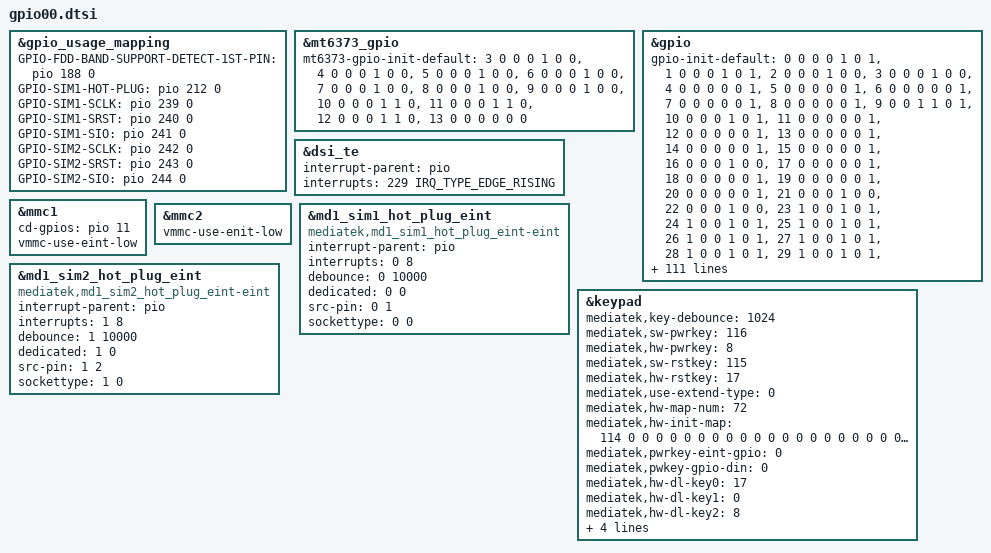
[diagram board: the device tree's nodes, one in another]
// SPDX-License-Identifier: (GPL-2.0 OR MIT)
/*
 * Copyright (C) 2022 MediaTek Inc.
 */
/*
 * Generated by MTK SP DrvGen Version: 3.5.160809 for MT6989.
 * 2024-03-19 13:16:16
 * Do Not Modify The File.
 * Copyright Mediatek Inc. (c) 2016.
 */

/*************************
 * ADC DTSI File
 ************************/



/*************************
 * CLK_BUF DTSI File
 ************************/



/*************************
 * I2C DTSI File
 ************************/



/*************************
 * GPIO DTSI File
 ************************/

&gpio_usage_mapping {
	GPIO-FDD-BAND-SUPPORT-DETECT-1ST-PIN = <&pio 188 0>;
	GPIO-SIM1-HOT-PLUG = <&pio 212 0>;
	GPIO-SIM1-SCLK = <&pio 239 0>;
	GPIO-SIM1-SRST = <&pio 240 0>;
	GPIO-SIM1-SIO = <&pio 241 0>;
	GPIO-SIM2-SCLK = <&pio 242 0>;
	GPIO-SIM2-SRST = <&pio 243 0>;
	GPIO-SIM2-SIO = <&pio 244 0>;
};

&mt6373_gpio{
	/* gpio1 and gpio2 has been reserved */
	mt6373-gpio-init-default = <3 0 0 0 1 0 0>,
	<4 0 0 0 1 0 0>,
	<5 0 0 0 1 0 0>,
	<6 0 0 0 1 0 0>,
	<7 0 0 0 1 0 0>,
	<8 0 0 0 1 0 0>,
	<9 0 0 0 1 0 0>,
	<10 0 0 0 1 1 0>,
	<11 0 0 0 1 1 0>,
	<12 0 0 0 1 1 0>,
	<13 0 0 0 0 0 0>;
};


&gpio{
	gpio-init-default = <0 0 0 0 1 0 1>,
		<1 0 0 0 1 0 1>,
		<2 0 0 0 1 0 0>,	/* NC */
		<3 0 0 0 1 0 0>,	/* TCON_RDY */
		<4 0 0 0 0 0 1>,
		<5 0 0 0 0 0 1>,
		<6 0 0 0 0 0 1>,
		<7 0 0 0 0 0 1>,
		<8 0 0 0 0 0 1>,
		<9 0 0 1 1 0 1>,
		<10 0 0 0 1 0 1>,
		<11 0 0 0 0 0 1>,
		<12 0 0 0 0 0 1>,
		<13 0 0 0 0 0 1>,
		<14 0 0 0 0 0 1>,
		<15 0 0 0 0 0 1>,
		<16 0 0 0 1 0 0>,	/* TCON_INT */
		<17 0 0 0 0 0 1>,
		<18 0 0 0 0 0 1>,
		<19 0 0 0 0 0 1>,
		<20 0 0 0 0 0 1>,
		<21 0 0 0 1 0 0>,	/* NC */
		<22 0 0 0 1 0 0>,	/* NC */
		<23 1 0 0 1 0 1>,
		<24 1 0 0 1 0 1>,
		<25 1 0 0 1 0 1>,
		<26 1 0 0 1 0 1>,
		<27 1 0 0 1 0 1>,
		<28 1 0 0 1 0 1>,
		<29 1 0 0 1 0 1>,
		<30 0 0 0 1 0 0>,
		<31 0 0 0 1 0 0>,
		<32 0 0 0 0 0 0>,
		<33 0 0 0 0 0 0>,
		<34 1 0 0 0 0 0>,
		<35 1 0 0 1 0 0>,
		<36 1 0 0 1 0 1>,
		<37 1 0 0 1 0 1>,
		<38 1 0 0 1 0 1>,
		<39 1 0 0 1 0 1>,
		<40 0 0 0 1 0 1>,
		<41 0 0 0 1 0 1>,
		<42 0 0 0 1 0 1>,
		<43 0 0 0 1 0 1>,
		<44 0 0 0 1 0 1>,
		<45 0 0 0 1 0 1>,
		<46 0 0 0 1 0 1>,
		<47 0 0 0 1 0 1>,
		<48 0 0 0 1 0 1>,
		<49 0 0 0 1 0 1>,
		<50 0 0 0 1 0 1>,
		<51 1 0 0 0 0 1>,
		<52 1 0 0 0 0 1>,
		<53 0 0 0 1 0 1>,
		<54 0 0 0 1 0 1>,
		<55 2 0 0 0 0 0>,
		<56 2 0 0 1 0 0>,
		<57 0 0 0 1 0 1>,
		<58 1 0 0 0 0 1>,
		<59 0 0 0 1 0 1>,
		<60 0 0 0 1 0 1>,
		<61 0 0 0 0 0 1>,
		<62 2 0 0 0 0 1>,
		<63 2 0 0 0 0 1>,
		<64 2 0 0 0 0 1>,
		<65 2 0 0 0 0 1>,
		<66 0 1 0 1 0 1>,
		<67 0 1 0 1 0 1>,
		<68 0 1 0 1 0 1>,
		<69 0 1 0 1 0 1>,
		<70 0 0 0 0 0 1>,
		<71 0 0 0 0 0 1>,
		<72 1 0 0 0 0 1>,
		<73 1 0 0 0 0 1>,
		<74 0 0 0 1 0 1>,
		<75 0 0 0 1 0 1>,
		<76 0 0 0 1 0 1>,
		<77 0 0 0 1 0 1>,
		<78 0 0 0 1 0 1>,	/* snvm i2c scl*/
		<79 0 0 0 1 0 1>,	/* snvm i2c sda */
		<80 0 0 0 1 0 0>,	/* NC */
		<81 0 0 0 1 0 1>,
		<82 0 0 0 1 0 1>,
		<83 0 0 0 1 0 1>,
		<84 0 1 0 0 0 1>,	/* aux switch sel */
		<85 0 0 0 0 0 1>,
		<86 0 1 0 0 2 0>,	/* OCTA_DCDC_EN */
		<87 0 1 1 0 0 1>,	/* aux switch en */
		<88 0 0 0 1 0 1>,
		<89 0 0 0 1 0 1>,
		<90 0 0 0 0 0 1>,
		<91 0 0 0 0 0 1>,
		<92 0 0 0 1 0 1>,
		<93 0 0 0 1 0 1>,
		<94 0 0 0 0 0 1>,
		<95 0 0 0 0 0 1>,
		<96 0 1 0 1 0 1>,
		<97 0 1 0 1 0 1>,
		<98 1 0 0 1 1 1>,
		<99 1 0 0 1 1 1>,
		<100 1 0 0 1 1 1>,
		<101 1 0 0 1 1 1>,
		<102 1 0 0 1 1 1>,
		<103 1 0 0 1 1 1>,
		<104 2 0 0 0 0 1>,
		<105 2 0 0 0 0 1>,
		<106 0 1 0 1 0 1>,	/* VTCAM_MCLK */
		<107 0 1 0 1 0 1>,
		<108 0 1 0 1 0 1>,
		<109 0 1 0 1 0 1>,
		<110 0 1 0 1 0 1>,
		<111 0 1 1 1 0 1>,
		<112 0 1 0 1 0 1>,
		<113 0 1 0 1 0 1>,
		<114 0 0 0 0 0 1>,
		<115 0 0 0 0 0 1>,
		<116 0 1 0 1 0 1>,	/* MAINCAM_MCLK */
		<117 0 1 0 1 0 1>,	/* UWCAM_MCLK */
		<118 0 0 0 1 0 1>,
		<119 0 0 0 1 0 1>,
		<120 1 0 0 1 1 1>,
		<121 1 0 0 1 1 1>,
		<122 0 0 0 1 0 0>,	/* NC */
		<123 0 0 0 1 0 0>,	/* NC */
		<124 0 1 0 1 0 1>,
		<125 0 1 0 1 0 1>,
		<126 0 0 0 1 0 0>,	/* NC */
		<127 0 0 0 1 0 0>,	/* NC */
		<128 1 0 0 1 1 1>,
		<129 1 0 0 1 1 1>,
		<130 1 0 0 1 1 1>,
		<131 1 0 0 1 1 1>,
		<132 1 0 0 1 0 1>,
		<133 1 0 0 1 0 1>,
		<134 1 0 0 1 0 1>,
		<135 0 0 0 1 0 1>,
		<136 0 0 0 1 0 1>,
		<137 0 0 0 1 0 1>,
		<138 0 0 0 1 0 1>,
		<139 0 0 0 0 0 1>,
		<140 0 0 0 0 0 1>,
		<141 1 0 0 0 0 1>,
		<142 1 0 0 1 1 1>,
		<143 1 0 0 1 0 1>,
		<144 1 0 0 1 0 1>,
		<145 1 0 0 1 0 1>,
		<146 1 0 0 1 0 1>,
		<147 1 0 0 1 0 1>,
		<148 1 0 0 0 0 1>,
		<149 1 0 0 1 1 1>,
		<150 0 1 0 1 0 1>,
		<151 0 1 0 1 0 1>,
		<152 0 1 1 1 0 1>,
		<153 0 1 0 1 0 1>,
		<154 0 0 0 1 0 1>,
		<155 0 1 0 1 0 1>,
		<156 0 0 0 1 0 1>,
		<157 0 1 0 1 0 1>,
		<158 0 0 0 1 1 1>,
		<159 1 0 0 1 1 1>,
		<160 1 0 0 1 1 1>,
		<161 1 0 0 1 1 1>,
		<162 1 0 0 1 1 1>,
		<163 1 0 0 1 1 1>,
		<164 1 0 0 1 1 1>,
		<165 1 0 0 0 0 1>,
		<166 1 0 0 0 0 1>,
		<167 1 0 0 0 0 1>,
		<168 1 0 0 0 0 1>,
		<169 1 0 0 1 0 1>,
		<170 1 0 0 0 0 1>,
		<171 1 0 0 0 0 1>,
		<172 1 0 0 0 0 1>,
		<173 1 0 0 0 0 1>,
		<174 0 1 0 1 0 1>,
		<175 0 0 0 0 0 1>,
		<176 1 0 0 1 1 1>,
		<177 1 0 0 1 1 1>,
		<178 0 0 0 1 0 1>,
		<179 0 0 0 1 0 1>,
		<180 0 0 0 1 0 1>,
		<181 0 0 0 1 0 1>,
		<182 0 0 0 1 0 1>,
		<183 0 0 0 0 0 1>,
		<184 0 0 0 0 0 1>,
		<185 0 0 0 0 0 1>,
		<186 0 0 0 0 0 1>,
		<187 0 0 0 1 0 1>,
		<188 0 0 0 0 0 1>,
		<189 0 0 0 0 0 1>,
		<190 0 0 0 0 0 1>,
		<191 0 0 0 1 0 1>,
		<192 0 0 0 1 0 0>,	/* NC */
		<193 0 0 0 0 0 1>,
		<194 0 0 0 0 0 1>,
		<195 1 0 0 0 0 1>,
		<196 0 0 0 1 1 1>,
		<197 0 1 0 1 0 1>,
		<198 7 0 0 1 0 1>,
		<199 7 0 0 1 0 1>,
		<200 7 0 0 1 0 1>,
		<201 7 0 0 0 0 1>,
		<202 7 0 0 1 0 1>,
		<203 1 0 0 0 0 1>,
		<204 1 0 0 1 1 1>,
		<205 0 0 0 1 0 1>,
		<206 0 0 0 1 0 1>,
		<207 0 1 0 1 0 1>,
		<208 0 1 0 1 0 1>,
		<209 0 0 0 1 0 1>,
		<210 0 0 0 0 0 1>,
		<211 0 0 0 0 2 0>,	/* DISP_CON_DET */
		<212 1 0 0 0 0 1>,
		<213 0 0 0 1 0 1>,
		<214 2 0 0 1 0 1>,
		<215 0 0 0 0 0 1>,
		<216 0 0 0 0 0 1>,
		<217 0 0 0 0 0 1>,
		<218 1 0 0 0 0 1>,
		<219 1 0 0 0 0 1>,
		<220 1 0 0 1 0 1>,
		<221 1 0 0 0 0 1>,
		<222 0 0 0 1 0 1>,
		<223 1 0 0 1 1 1>,
		<224 1 0 0 1 1 1>,
		<225 1 0 0 1 1 1>,
		<226 1 0 0 1 1 1>,
		<227 0 0 0 1 0 1>,
		<228 0 0 0 1 0 1>,
		<229 1 0 0 1 0 1>,
		<230 0 1 0 0 2 0>,	/* DISP_RST */
		<231 0 0 0 0 0 1>,
		<232 0 0 0 0 0 1>,
		<233 0 0 0 1 0 0>,	/* NC */
		<234 0 0 0 0 0 1>,
		<235 1 0 0 1 0 1>,
		<236 1 0 0 1 1 1>,
		<237 1 0 0 1 0 1>,
		<238 1 0 0 1 0 1>,
		<239 1 0 0 0 0 1>,
		<240 1 0 0 0 0 1>,
		<241 1 0 0 1 1 1>,
		<242 1 0 0 0 0 1>,
		<243 1 0 0 0 0 1>,
		<244 1 0 0 1 1 1>,
		<245 1 0 0 0 0 1>,
		<246 1 0 0 1 1 1>,
		<247 1 0 0 1 1 1>,
		<248 1 0 0 1 1 1>,
		<249 1 0 0 1 1 1>,
		<250 1 0 0 1 1 1>;
};


/*************************
 * EINT DTSI File
 ************************/

#include <dt-bindings/interrupt-controller/irq.h>
#include <dt-bindings/interrupt-controller/arm-gic.h>
#include <dt-bindings/gpio/gpio.h>


&dsi_te {
	interrupt-parent = <&pio>;
	interrupts = <229 IRQ_TYPE_EDGE_RISING>;
	status = "okay";
};

&mmc1 {
	cd-gpios = <&pio 11 GPIO_ACTIVE_HIGH>;
	vmmc-use-eint-low;
};

&mmc2 {
	vmmc-use-enit-low;
};

/*************************
 * MD1_EINT DTSI File
 ************************/

&md1_sim1_hot_plug_eint {
	compatible = "mediatek,md1_sim1_hot_plug_eint-eint";
	interrupt-parent = <&pio>;
	interrupts = <0 8>;
	debounce = <0 10000>;
	dedicated = <0 0>;
	src-pin = <0 1>;
	sockettype = <0 0>;
	status = "okay";
};

&md1_sim2_hot_plug_eint {
	compatible = "mediatek,md1_sim2_hot_plug_eint-eint";
	interrupt-parent = <&pio>;
	interrupts = <1 8>;
	debounce = <1 10000>;
	dedicated = <1 0>;
	src-pin = <1 2>;
	sockettype = <1 0>;
	status = "okay";
};



/*************************
 * PMIC DTSI File
 ************************/



/*************************
 * POWER DTSI File
 ************************/



/*************************
 * KPD DTSI File
 ************************/

&keypad {
	mediatek,key-debounce = <1024>;
	mediatek,sw-pwrkey = <116>;
	mediatek,hw-pwrkey = <8>;
	mediatek,sw-rstkey  = <115>;
	mediatek,hw-rstkey = <17>;
	mediatek,use-extend-type = <0>;
	/*HW Keycode [0~71] -> Linux Keycode*/
	mediatek,hw-map-num = <72>;
	mediatek,hw-init-map = <114 0 0 0 0 0 0 0 0 0 0 0 0 0 0 0 0 0 0 0 0 0 0 0
				0 0 0 0 0 0 0 0 0 0 0 0 0 0 0 0 0 0 0 0 0 0 0 0
				0 0 0 0 0 0 0 0 0 0 0 0 0 0 0 0 0 0 0 0 0 0 0 0 >;
	mediatek,pwrkey-eint-gpio = <0>;
	mediatek,pwkey-gpio-din  = <0>;
	mediatek,hw-dl-key0 = <17>;
	mediatek,hw-dl-key1 = <0>;
	mediatek,hw-dl-key2 = <8>;
	mediatek,hw-recovery-key = <17>;
	mediatek,hw-factory-key = <0>;
	mediatek,gpio-key-index = <216>;
	/*factory-key-type*/
	/*0: Keypad IP key*/
	/*1: GPIO key*/
	/*2: HOME2 key*/
	mediatek,factory-key-type = <1>;
	status = "okay";
};


